# R7FA0L107 register map
Vendor: Renesas Electronics Corporation; Series: RA0; File version: 1.10.01
CPU: CM23 r1p0, little endian, no MPU, no FPU, VTOR, 2 interrupt priority bits, 64 interrupts
Registers are 16-bit, read-write, reset 0x0 unless marked. A register's access mark holds for its fields unless they carry their own. Offsets are from the block's base; [hi:lo] are bit positions; {n}, {i} and the like mark numbered series.

## FLCN — Flash I/O Registers
Base 0x407EC000
0x90 DFLCTL 8-bit — Data Flash Control Register
  [0] DFLEN — Data Flash Access Enable
    0=Access to the data flash is disabled; 1=Access to the data flash is enabled
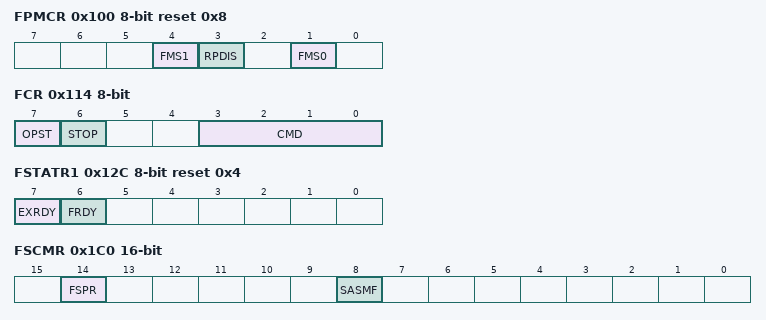
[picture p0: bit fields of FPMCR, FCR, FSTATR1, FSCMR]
0x100 FPMCR 8-bit reset 0x8 — Flash P/E Mode Control Register
  [4] FMS1 — Flash Operating Mode Select 1
  [3] RPDIS — Code Flash P/E Disable
    0=Programming of the code flash is enabled; 1=Programming of the code flash is disabled
  [1] FMS0 — Flash Operating Mode Select 0
    0=FMS1 = 0: Read mode FMS1 = 1: Data flash P/E mode; 1=FMS1 = 0: Code flash P/E mode FMS1 = 1: Setting prohibited
0x104 FASR 8-bit — Flash Area Select Register
  [0] EXS — Extra Area Select
    0=User area or data area; 1=Extra area
0x108 FSARL — Flash Processing Start Address Register L
  [15:0] FSARL — Flash Processing Start Address L
0x110 FSARH — Flash Processing Start Address Register H
  [15:0] FSARH — Flash Processing Start Address H
0x114 FCR 8-bit — Flash Control Register
  [7] OPST — Processing Start
    0=Processing stops; 1=Processing starts
  [6] STOP — Forced Processing Stop
  [3:0] CMD — Software Command Setting
    1=Program; 3=Blank check (code flash); 4=Block erase; 11=Blank check (data flash); other=Others (Setting prohibited)
0x118 FEARL — Flash Processing End Address Register L
  [15:0] FEARL — Flash Processing End Address L
0x120 FEARH — Flash Processing End Address Register H
  [15:0] FEARH — Flash Processing End Address H
0x124 FRESETR 8-bit — Flash Reset Register
  [0] FRESET — Software Reset of the Registers
    0=The registers related to the flash programming are not reset; 1=The registers related to the flash programming are reset
0x12C FSTATR1 8-bit ro reset 0x4 — Flash Status Register 1
  [7] EXRDY — Extra Area Ready Flag
    0=The software command of the FEXCR register is not terminated; 1=The software command of the FEXCR register is terminated
  [6] FRDY — Flash Ready Flag
    0=The software command of the FCR register is not terminated; 1=The software command of the FCR register is terminated
0x130 FWBL0 — Flash Write Buffer Register L0
  [15:0] WDATA — Flash Write Buffer L0
0x138 FWBH0 — Flash Write Buffer Register H0
  [15:0] WDATA — Flash Write Buffer H0
0x180 FPR 8-bit wo reset not defined — Protection Unlock Register
  [7:0] FPR — Protection Unlock
0x184 FPSR 8-bit ro — Protection Unlock Status Register
  [0] PERR — Protect Error Flag
    0=No error; 1=An error occurs
0x1C0 FSCMR ro (reset mask 0xBEFF) — Flash Startup Setting Monitor Register
  [14] FSPR — Access Window Protection Flag
    0=Access window setting disabled; 1=Access window setting enabled
  [8] SASMF — Startup Area Setting Monitor Flag
    0=Setting to start up using the alternative area; 1=Setting to start up using the default area
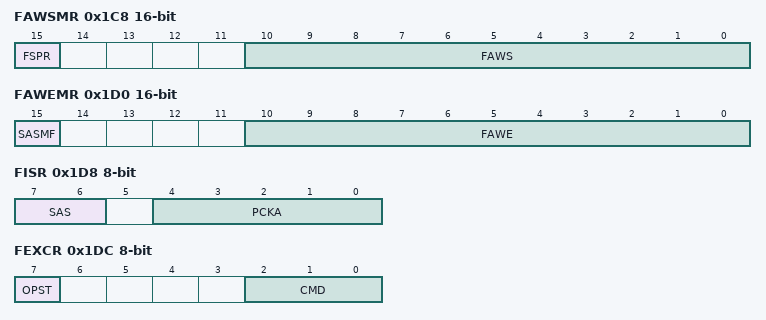
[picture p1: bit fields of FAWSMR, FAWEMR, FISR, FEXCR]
0x1C8 FAWSMR ro (reset mask 0x7800) — Flash Access Window Start Address Monitor Register
  [15] FSPR — Access Window Protection Flag
  [10:0] FAWS — Access Window Start Address
0x1D0 FAWEMR ro (reset mask 0x7800) — Flash Access Window End Address Monitor Register
  [15] SASMF — Startup Area Setting Monitor Flag
  [10:0] FAWE — Access Window End Address
0x1D8 FISR 8-bit — Flash Initial Setting Register
  [7:6] SAS — Startup Area Select
    2=The startup area is switched to the default area temporarily; 3=The startup area is switched to the alternate area temporarily; other=Others (The startup area is selected according to the settings of the extra area.)
  [4:0] PCKA — Flash-IF Clock Notification
0x1DC FEXCR 8-bit — Flash Extra Area Control Register
  [7] OPST — Processing Start
    0=Processing stops; 1=Processing starts
  [2:0] CMD — Software Command Setting
    2=Access window information program Startup area selection and security setting; {v}=OCDID{v-2} program (v=3..6); other=Others (Setting prohibited)
0x1E0 FEAML ro — Flash Error Address Monitor Register L
0x1E8 FEAMH ro — Flash Error Address Monitor Register H
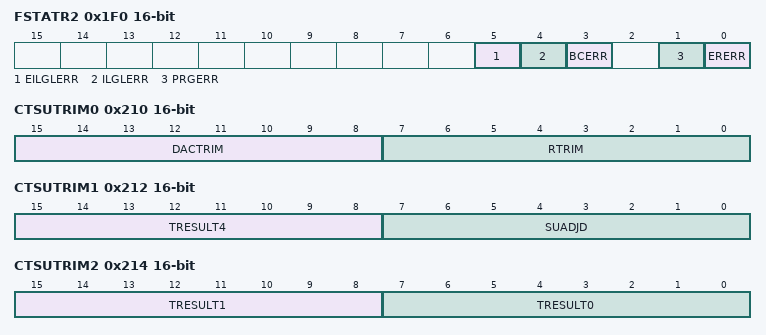
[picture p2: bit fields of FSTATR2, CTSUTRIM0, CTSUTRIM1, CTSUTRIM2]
0x1F0 FSTATR2 ro — Flash Status Register 2
  [5] EILGLERR — Extra Area Illegal Command Error Flag
    0=No illegal command or illegal access to the extra area is detected; 1=An illegal command or illegal access to the extra area is detected
  [4] ILGLERR — Illegal Command Error Flag
    0=No illegal software command or illegal access is detected; 1=An illegal command or illegal access is detected
  [3] BCERR — Blank Check Error Flag
    0=Blank checking terminates normally; 1=An error occurs during blank checking
  [1] PRGERR — Program Error Flag
    0=Programming terminates normally; 1=An error occurs during programming
  [0] ERERR — Erase Error Flag
    0=Erasure terminates normally; 1=An error occurs during erasure
0x200 HIOTRM 8-bit (reset mask 0xC0) — High-speed On-chip Oscillator Trimming Register
  [5:0] HIOTRM — HOCO User Trimming
0x20A FLMODE 8-bit reset 0x80 — Flash Operating Mode Control Register
  [7:6] MODE — Operating Mode Select
    0=Setting prohibited; 1=Low-speed mode; 2=Middle-speed mode; 3=High-speed mode
0x20B FLMWRP 8-bit — Flash Operating Mode Protect Register
  [0] FLMWEN — Control of Flash Operation Mode Select Register
    0=Rewriting the FLMODE register is disabled; 1=Rewriting the FLMODE register is enabled
0x210 CTSUTRIM0 reset not defined — CTSU Trimming Register 0
  [15:8] DACTRIM — Linearity Adjustment of Offset Current
  [7:0] RTRIM — CTSU Reference Resistance Adjustment
0x212 CTSUTRIM1 reset not defined — CTSU Trimming Register 1
  [15:8] TRESULT4 — Coefficient of variation for the reference load resistance
  [7:0] SUADJD — CTSU SUCLK Frequency Adjustment
0x214 CTSUTRIM2 reset not defined — CTSU Trimming Register 2
  [15:8] TRESULT1 — The coefficient of variation for the 15 kΩ reference load resistance is stored.
  [7:0] TRESULT0 — The coefficient of variation for the 7.5 kΩ reference load resistance is stored.
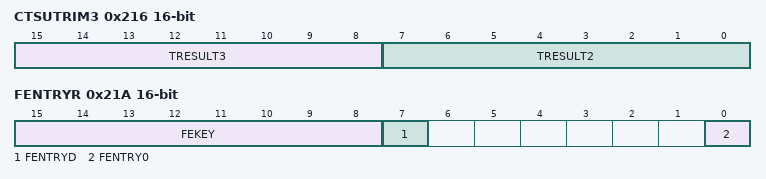
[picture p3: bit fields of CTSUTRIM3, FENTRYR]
0x216 CTSUTRIM3 reset not defined — CTSU Trimming Register 3
  [15:8] TRESULT3 — The coefficient of variation for the 60 kΩ reference load resistance is stored.
  [7:0] TRESULT2 — The coefficient of variation for the 30 kΩ reference load resistance is stored.
0x21A FENTRYR — Flash P/E Mode Entry Register
  [15:8] FEKEY wo — Key Code
  [7] FENTRYD — Data Flash P/E Mode Entry
    0=The data flash is the read mode; 1=The data flash is the P/E mode
  [0] FENTRY0 — Code Flash P/E Mode Entry 0
    0=The code flash is the read mode; 1=The code flash is the P/E mode
